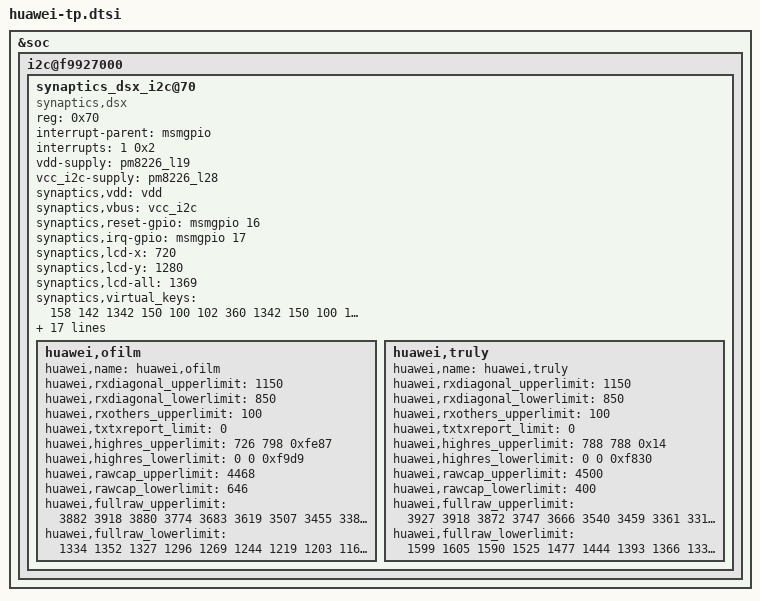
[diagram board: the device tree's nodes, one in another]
/*Add synaptics new driver "Synaptics DSX I2C V2.0"*/
&soc{
	i2c@f9927000 {
		status = "ok";
		synaptics_dsx_i2c@70 {
			compatible = "synaptics,dsx";
			reg = <0x70>;
			interrupt-parent = <&msmgpio>;
			interrupts = <1 0x2>;
			vdd-supply = <&pm8226_l19>;
			vcc_i2c-supply = <&pm8226_l28>;
			synaptics,vdd = "vdd";
			synaptics,vbus = "vcc_i2c";
			synaptics,reset-gpio = <&msmgpio 16 0x00>;
			synaptics,irq-gpio = <&msmgpio 17 0x00>;

			synaptics,lcd-x = <720>;
			synaptics,lcd-y = <1280>;
			synaptics,lcd-all = <1369>;
			synaptics,virtual_keys = /* KeyCode CenterX CenterY Width Height */
				/* KEY_BACK */
				<158 142 1342 150 100
				/* KEY_HOME(102) */
				102 360 1342 150 100
				/* KEY_MENU */
				139 578 1342 150 100>;

			/* SYNAPTICS_WAKE_UP_GESTURE_FLAG:'1'->enabled,'0'->disabled */
			/*IC flash is not enough for holster,so del one gesture*/
			synaptics,gesture_enabled = <0>;
			/* Gestures that supported:                           */
			/* bit0  Double tap                                        */
			/* bit1  Single finger slide from left to right     */
			/* bit2  Single finger slide from right to left     */
			/* bit3  Single finger slide from top to bottom  */
			/* bit4  Single finger slide from bottom to top  */
			/* bit5  Double finger slide from top to bottom--disable for holster*/
			/* bit6  Single finger slide circle                     */
			/* bit7  Single finger write letter c                  */
			/* bit8  Single finger write letter e                  */
			/* bit9  Single finger write letter m                 */
			/* bit10 Single finger write letter w                 */
			/* bit11 Palm off screen                                */
			synaptics,easy_wakeup_supported_gestures = <0xFDF>;

			/*Defination of report key value  for different gestures*/
			synaptics,easy_wakeup_gesture_keys = 
			<	59 /*0.Double tap:KEY_F1*/
				60 /*1.Single finger slide from left to right*/
				61 /*2.Single finger slide from right to left:KEY_F3*/
				62 /*3.Single finger slide from top to bottom*/
				63 /*4.Single finger slide from bottom to top:KEY_F5*/
				64 /*5.Double finger slide from top to bottom*/
				65 /*6.Single finger slide circle:KEY_F7*/
				66 /*7.Single finger write letter c*/
				67 /*8.Single finger write letter e:KEY_F9*/
				68 /*9.Single finger write letter m*/
				87 /*10.Single finger write letter w:KEY_F11*/
				88 /*11.Palm off screen*/
			>;

			/* Double-tap-zone defined by huawei */
			/* Shielded area is:1cm left,1cm right,3cm up,2cm down */
			huawei,dtz_x0 = <116>;
			huawei,dtz_y0 = <349>;
			huawei,dtz_x1 = <604>;
			huawei,dtz_y1 = <1047>;

			/* SYNAPTICS_GLOVE_FUNCTION_FLAG:'1'->enabled,'0'->disabled*/
			synaptics,glove_enabled = <0>;
			/*After reduce power-consumption by exit reduce mode,*/
			/*we have to reduce f-r rate to make sure gesture work fine*/
			synaptics,fast_relax_gesture = <7>;
			/*Holster support flag*/
			synaptics,holster_supported = <1>;

			synaptics,reset-on-status = <0>;
			synaptics,power-delay-ms = <160>;
			synaptics,reset-delay-ms = <100>;
			synaptics,reset-active-ms = <90>;
			synaptics,product_name = "g660L";

			/*capacitance self-adapt*/
			/*To adjust the cutting angle threshold to the maximum range*/
			huawei,ofilm {
				huawei,name = "huawei,ofilm";
				huawei,rxdiagonal_upperlimit = <1150>;
				huawei,rxdiagonal_lowerlimit = <850>;
				huawei,rxothers_upperlimit = <100>;
				huawei,txtxreport_limit = <0>;
				huawei,highres_upperlimit = <726 798 0xfe87>;/*0xfe87==-377*/
				huawei,highres_lowerlimit = <0 0 0xf9d9>;/*0xf9d9==-1575*/
				huawei,rawcap_upperlimit = <4468>;
				huawei,rawcap_lowerlimit = <646>;

				huawei,fullraw_upperlimit =
					<3882 3918 3880 3774 3683 3619 3507 3455 3385 3312 3292 3197 4037 3977 3910 3885 3836 3827 3792 3771 3752 3705 3689 9999 
					4050 4141 4093 3985 3894 3823 3724 3665 3598 3500 3441 3358 3914 3920 3868 3802 3801 3794 3760 3759 3736 3707 3687 3627 
					4072 4162 4110 4001 3908 3843 3745 3684 3619 3522 3460 3378 3830 3831 3770 3710 3714 3687 3663 3656 3637 3621 3591 3616 
					4085 4177 4124 4016 3929 3855 3785 3705 3644 3540 3479 3392 3752 3757 3672 3631 3619 3592 3570 3563 3540 3530 3495 3549 
					4107 4201 4144 4034 3959 3875 3787 3732 3670 3567 3504 3424 3675 3689 3595 3557 3542 3516 3484 3486 3452 3430 3409 3473 
					4111 4226 4166 4069 3999 3899 3808 3756 3697 3606 3542 3466 3603 3621 3528 3477 3463 3441 3406 3402 3379 3355 3325 3397 
					4159 4257 4204 4107 4025 3936 3859 3801 3732 3654 3584 3515 3550 3582 3472 3410 3404 3374 3343 3332 3315 3301 3264 3330 
					4191 4293 4239 4141 4074 3983 3914 3840 3785 3711 3640 3584 3491 3533 3423 3353 3343 3325 3278 3280 3255 3222 3207 3292 
					4230 4340 4275 4180 4139 4060 3966 3907 3840 3760 3700 3658 3444 3495 3385 3302 3299 3287 3232 3232 3201 3169 3155 3248 
					4261 4382 4316 4222 4180 4103 4022 3966 3889 3851 3777 3728 3416 3470 3357 3269 3263 3257 3199 3190 3165 3130 3115 3235 
					4299 4431 4359 4274 4235 4163 4095 4036 3963 3932 3850 3819 3382 3445 3329 3249 3236 3221 3162 3161 3144 3096 3080 3207 
					4334 4464 4415 4338 4302 4240 4162 4113 4033 4016 3936 3913 3354 3423 3308 3224 3213 3200 3134 3130 3113 3068 3098 3486 
					4278 4422 4356 4306 4256 4197 4125 4095 4025 3971 3934 3894 3193 3218 3185 3147 3106 3129 3077 3060 3022 3032 3010 9999>;

				huawei,fullraw_lowerlimit =
					<1334 1352 1327 1296 1269 1244 1219 1203 1168 1155 1125 1100 1308 1298 1283 1281 1280 1264 1251 1251 1240 1232 1225 0 
					1336 1370 1348 1317 1283 1262 1235 1221 1183 1172 1141 1117 1230 1221 1216 1215 1198 1185 1175 1182 1164 1157 1164 1241 
					1274 1373 1350 1313 1283 1259 1235 1217 1178 1169 1136 1111 1198 1194 1188 1181 1161 1149 1139 1151 1127 1118 1125 1163 
					1363 1371 1360 1326 1293 1268 1245 1226 1194 1176 1150 1125 1184 1176 1172 1166 1150 1137 1124 1130 1116 1106 1110 1149 
					1358 1383 1365 1331 1299 1276 1254 1236 1191 1185 1149 1125 1156 1156 1149 1137 1116 1101 1091 1105 1080 1072 1074 1110 
					1344 1379 1364 1331 1296 1272 1247 1229 1191 1180 1148 1125 1133 1130 1125 1113 1093 1076 1064 1079 1054 1043 1043 1076 
					1301 1364 1355 1339 1307 1280 1256 1236 1214 1189 1164 1152 1127 1120 1116 1109 1102 1089 1073 1062 1061 1054 1053 1075 
					1317 1403 1380 1349 1311 1286 1261 1247 1220 1196 1173 1161 1113 1107 1101 1094 1086 1071 1056 1046 1043 1034 1032 1065 
					1400 1410 1392 1358 1323 1298 1270 1251 1226 1204 1184 1171 1104 1097 1091 1083 1075 1067 1049 1031 1028 1028 1021 1058 
					1415 1413 1399 1367 1337 1308 1283 1270 1243 1218 1147 1074 978  986  965  971  950  944  921  937  926  909  906  932  
					1423 1430 1409 1376 1346 1319 1296 1279 1252 1233 1209 1199 1088 1079 1073 1064 1057 1050 1031 1013 1012 1010 1001 1046 
					1424 1438 1422 1391 1359 1339 1314 1300 1275 1252 1231 1221 1087 1076 1073 1064 1053 1048 1031 1011 1008 1008 1001 1118 
					1444 1467 1454 1437 1411 1393 1373 1356 1327 1308 1286 1280 1069 1058 1052 1044 1034 1030 1013 993  990  990  897  0>;
			};
			huawei,truly {
				huawei,name = "huawei,truly";
				huawei,rxdiagonal_upperlimit = <1150>;
				huawei,rxdiagonal_lowerlimit = <850>;
				huawei,rxothers_upperlimit = <100>;
				huawei,txtxreport_limit = <0>;
				/*To adjust highresistance threshold*/
				huawei,highres_upperlimit = <788 788 0x14>;/*0x14==20*/
				huawei,highres_lowerlimit = <0 0 0xf830>;/*0xf830==-2000*/
				huawei,rawcap_upperlimit = <4500>;
				huawei,rawcap_lowerlimit = <400>;
				huawei,fullraw_upperlimit =
					<3927 3918 3872 3747 3666 3540 3459 3361 3315 3213 3152 3042 3943 3892 3823 3802 3756 3712 3676 3642 3633 3624 3592 9999
					4110 4117 4078 3953 3893 3754 3686 3571 3558 3463 3351 3273 3907 3799 3781 3742 3736 3694 3655 3648 3610 3623 3598 3533
					4125 4132 4096 3973 3918 3795 3721 3616 3602 3512 3402 3319 3843 3750 3714 3679 3672 3651 3588 3579 3536 3547 3528 3557
					4145 4162 4128 4008 3948 3831 3757 3656 3638 3557 3432 3364 3778 3663 3634 3607 3592 3556 3497 3495 3455 3462 3446 3507
					4172 4193 4156 4027 4025 3861 3782 3696 3661 3581 3472 3395 3693 3630 3551 3508 3495 3467 3414 3400 3357 3367 3353 3403
					4195 4232 4190 4079 4020 3910 3878 3787 3617 3620 3533 3487 3628 3540 3477 3455 3427 3420 3350 3336 3294 3299 3277 3337
					4230 4271 4230 4110 4058 3956 3967 3809 3724 3677 3565 3532 3578 3477 3427 3393 3374 3358 3284 3277 3231 3245 3222 3271
					4265 4303 4260 4141 4095 3997 4005 3812 3794 3752 3616 3564 3521 3414 3362 3329 3311 3278 3218 3215 3168 3179 3155 3238
					4316 4338 4299 4188 4152 4086 4006 3854 3925 3857 3670 3624 3476 3388 3337 3302 3273 3259 3175 3171 3126 3131 3106 3201
					4356 4380 4352 4244 4225 4110 4040 3929 4009 3894 3774 3694 3438 3382 3305 3262 3239 3218 3133 3130 3081 3091 3053 3158
					4391 4429 4401 4305 4256 4162 4095 4085 4096 3924 3868 3773 3413 3309 3260 3220 3204 3178 3105 3099 3047 3053 3017 3122
					4433 4478 4457 4363 4313 4223 4174 4121 4111 3990 3889 3848 3368 3269 3203 3168 3148 3120 3036 3039 2983 2990 2952 3173
					4389 4456 4442 4359 4307 4230 4167 4096 4096 4026 3924 3880 3196 3098 3035 2996 2980 2947 2871 2877 2822 2823 2760 9999>;

				huawei,fullraw_lowerlimit =
					<1599 1605 1590 1525 1477 1444 1393 1366 1331 1302 1278 1240 1637 1600 1574 1538 1548 1507 1488 1498 1492 1470 1474 0
					1669 1681 1667 1598 1554 1525 1472 1466 1414 1385 1362 1321 1589 1566 1558 1533 1525 1516 1509 1499 1496 1478 1490 1433
					1673 1685 1675 1613 1568 1537 1490 1488 1433 1404 1381 1341 1558 1539 1527 1502 1493 1484 1483 1460 1464 1444 1455 1456
					1680 1698 1685 1625 1580 1550 1505 1484 1448 1418 1397 1358 1520 1490 1492 1463 1459 1449 1432 1421 1425 1397 1420 1434
					1694 1707 1698 1637 1592 1542 1520 1514 1464 1435 1415 1376 1485 1475 1460 1422 1427 1417 1418 1385 1392 1359 1383 1397
					1700 1720 1706 1647 1600 1580 1533 1530 1479 1446 1427 1392 1463 1441 1425 1379 1374 1382 1386 1351 1356 1328 1346 1363
					1715 1737 1719 1666 1620 1599 1562 1548 1503 1443 1443 1416 1439 1418 1401 1332 1369 1356 1360 1325 1326 1301 1318 1332
					1732 1751 1737 1682 1644 1619 1600 1571 1501 1449 1466 1439 1415 1395 1356 1352 1343 1331 1334 1295 1300 1272 1288 1314
					1748 1772 1755 1701 1663 1636 1613 1570 1516 1542 1506 1469 1383 1359 1362 1331 1320 1309 1310 1271 1277 1246 1264 1296
					1754 1790 1773 1724 1691 1661 1586 1602 1578 1574 1536 1500 1320 1360 1343 1310 1302 1292 1294 1256 1265 1230 1244 1279
					1776 1806 1794 1747 1712 1649 1623 1664 1607 1604 1566 1532 1344 1344 1327 1295 1286 1275 1277 1244 1246 1218 1224 1259
					1800 1823 1821 1775 1729 1715 1681 1693 1623 1619 1598 1566 1337 1326 1308 1276 1269 1257 1257 1220 1220 1192 1203 1284
					1793 1814 1804 1758 1726 1704 1668 1672 1602 1599 1580 1550 1232 1227 1209 1176 1170 1160 1160 1120 1127 1089 1091 0>;
			};
		};
	};
};

